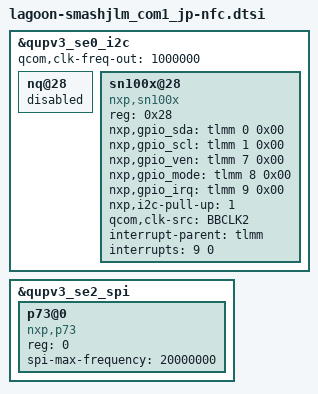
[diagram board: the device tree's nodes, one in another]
// SPDX-License-Identifier: GPL-2.0-only
/*
 * Copyright (c) 2018-2019, The Linux Foundation. All rights reserved.
 */

#include "../lagoon-smashjlm_common/lagoon-smashjlm_common-nfc.dtsi"

&qupv3_se0_i2c {
    status = "ok";
    qcom,clk-freq-out = <1000000>;
    #address-cells = <1>;
    #size-cells = <0>;

    nq@28 {
        status = "disabled";
    };

    sn100x@28 {
        compatible = "nxp,sn100x";
        reg = <0x28>;
        status = "ok";
        nxp,gpio_sda = <&tlmm 0 0x00>;
        nxp,gpio_scl = <&tlmm 1 0x00>;
        nxp,gpio_ven = <&tlmm 7 0x00>;
        nxp,gpio_mode = <&tlmm 8 0x00>;
        nxp,gpio_irq = <&tlmm 9 0x00>;
        nxp,i2c-pull-up = <1>;
        qcom,clk-src = "BBCLK2";
        interrupt-parent = <&tlmm>;
        interrupts = <9 0>;
        interrupt-names = "nfc_irq";
    };
};

&qupv3_se2_spi {
    status = "ok";

    p73@0 {
        compatible = "nxp,p73";
        reg = <0>;
        status = "ok";
        spi-max-frequency = <20000000>;
    };
};

